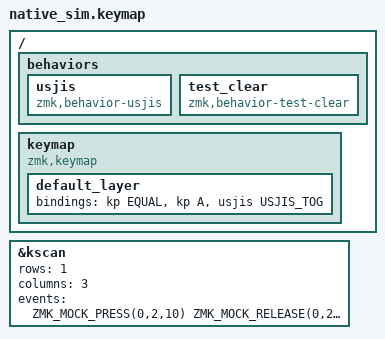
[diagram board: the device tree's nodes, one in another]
/* Generated by tests/zmk/generate.py; do not edit. */
#include <dt-bindings/zmk/keys.h>
#include <behaviors.dtsi>
#include <dt-bindings/zmk/kscan_mock.h>
#include <dt-bindings/zmk/usjis.h>

&kscan {
    rows = <1>;
    columns = <3>;
    events = <
        ZMK_MOCK_PRESS(0,2,10)
        ZMK_MOCK_RELEASE(0,2,300)
        ZMK_MOCK_PRESS(0,2,10)
        ZMK_MOCK_RELEASE(0,2,300)
        ZMK_MOCK_PRESS(0,2,10)
        ZMK_MOCK_RELEASE(0,2,2100)
        ZMK_MOCK_PRESS(0,0,10)
        ZMK_MOCK_PRESS(0,2,10)
        ZMK_MOCK_RELEASE(0,2,2500)
        ZMK_MOCK_RELEASE(0,0,2100)
        ZMK_MOCK_PRESS(0,1,10)
        ZMK_MOCK_PRESS(0,2,10)
        ZMK_MOCK_RELEASE(0,2,10)
        ZMK_MOCK_PRESS(0,2,10)
        ZMK_MOCK_RELEASE(0,2,10)
        ZMK_MOCK_RELEASE(0,1,2100)
        ZMK_MOCK_PRESS(0,2,10)
        ZMK_MOCK_RELEASE(0,2,1900)
        ZMK_MOCK_PRESS(0,2,10)
        ZMK_MOCK_RELEASE(0,2,1900)
        ZMK_MOCK_PRESS(0,2,10)
        ZMK_MOCK_RELEASE(0,2,2100)
    >;
};

/ {
    behaviors {
        usjis: usjis {
            compatible = "zmk,behavior-usjis";
            #binding-cells = <1>;
        };
        test_clear: test_clear {
            compatible = "zmk,behavior-test-clear";
            #binding-cells = <0>;
        };
    };
};

/ {
    keymap {
        compatible = "zmk,keymap";
        default_layer {
            bindings = <
                &kp EQUAL
                &kp A
                &usjis USJIS_TOG
            >;
        };
    };
};
